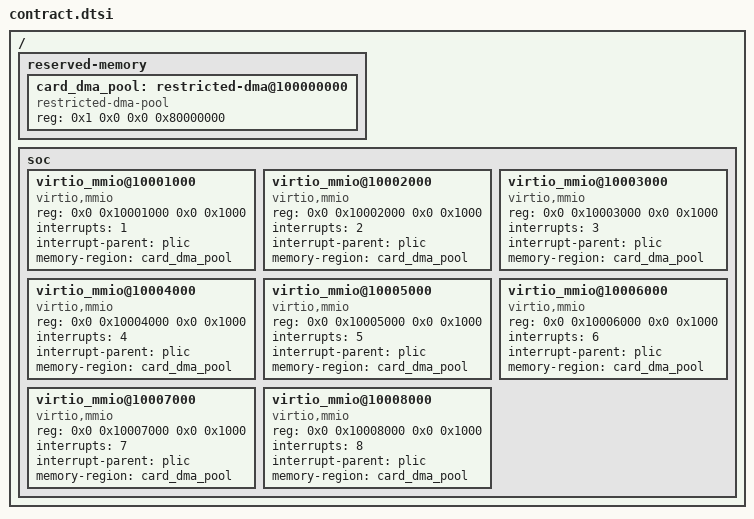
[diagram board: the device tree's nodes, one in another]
/* Generated from soc/src/main/scala/card/contract/Contract.scala by Generate.scala. Do not edit. */
/* The card's virtio-mmio slots and its DMA region (DDR3 channel B). Every virtio buffer and ring a
 * driver allocates comes from the restricted DMA pool, so it lies inside the card's DMA window.
 * The including tree provides the PLIC with the label `plic`. */
/ {
	reserved-memory {
		#address-cells = <2>;
		#size-cells = <2>;
		ranges;
		card_dma_pool: restricted-dma@100000000 {
			compatible = "restricted-dma-pool";
			reg = <0x1 0x0 0x0 0x80000000>;
		};
	};
	soc {
		#address-cells = <2>;
		#size-cells = <2>;
		virtio_mmio@10001000 {
			compatible = "virtio,mmio";
			reg = <0x0 0x10001000 0x0 0x1000>;
			interrupts = <1>;
			interrupt-parent = <&plic>;
			memory-region = <&card_dma_pool>;
		};
		virtio_mmio@10002000 {
			compatible = "virtio,mmio";
			reg = <0x0 0x10002000 0x0 0x1000>;
			interrupts = <2>;
			interrupt-parent = <&plic>;
			memory-region = <&card_dma_pool>;
		};
		virtio_mmio@10003000 {
			compatible = "virtio,mmio";
			reg = <0x0 0x10003000 0x0 0x1000>;
			interrupts = <3>;
			interrupt-parent = <&plic>;
			memory-region = <&card_dma_pool>;
		};
		virtio_mmio@10004000 {
			compatible = "virtio,mmio";
			reg = <0x0 0x10004000 0x0 0x1000>;
			interrupts = <4>;
			interrupt-parent = <&plic>;
			memory-region = <&card_dma_pool>;
		};
		virtio_mmio@10005000 {
			compatible = "virtio,mmio";
			reg = <0x0 0x10005000 0x0 0x1000>;
			interrupts = <5>;
			interrupt-parent = <&plic>;
			memory-region = <&card_dma_pool>;
		};
		virtio_mmio@10006000 {
			compatible = "virtio,mmio";
			reg = <0x0 0x10006000 0x0 0x1000>;
			interrupts = <6>;
			interrupt-parent = <&plic>;
			memory-region = <&card_dma_pool>;
		};
		virtio_mmio@10007000 {
			compatible = "virtio,mmio";
			reg = <0x0 0x10007000 0x0 0x1000>;
			interrupts = <7>;
			interrupt-parent = <&plic>;
			memory-region = <&card_dma_pool>;
		};
		virtio_mmio@10008000 {
			compatible = "virtio,mmio";
			reg = <0x0 0x10008000 0x0 0x1000>;
			interrupts = <8>;
			interrupt-parent = <&plic>;
			memory-region = <&card_dma_pool>;
		};
	};
};
